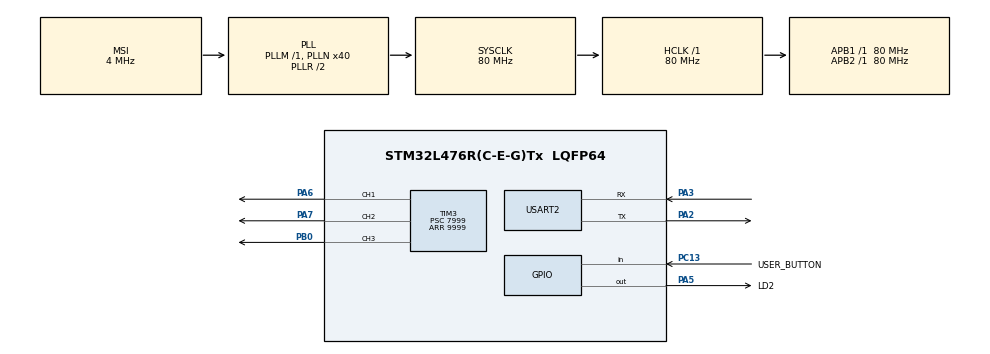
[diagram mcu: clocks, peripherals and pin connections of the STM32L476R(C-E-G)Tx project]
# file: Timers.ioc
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Mcu.Family=STM32L4
Mcu.Name=STM32L476R(C-E-G)Tx
Mcu.Package=LQFP64
NVIC.PriorityGroup=NVIC_PRIORITYGROUP_4
NVIC.TIM3_IRQn=true\:10\:0\:true\:false\:true\:true\:true\:true
PA13\ (JTMS-SWDIO).Mode=Serial_Wire
PA13\ (JTMS-SWDIO).Signal=SYS_JTMS-SWDIO
PA14\ (JTCK-SWCLK).Mode=Serial_Wire
PA14\ (JTCK-SWCLK).Signal=SYS_JTCK-SWCLK
PA2.Mode=Asynchronous
PA2.Signal=USART2_TX
PA3.Mode=Asynchronous
PA3.Signal=USART2_RX
PA5.GPIO_Label=LD2
PA5.Signal=GPIO_Output
PA6.Signal=S_TIM3_CH1
PA7.Signal=S_TIM3_CH2
PB0.Signal=S_TIM3_CH3
PC13.GPIO_Label=USER_BUTTON
PC13.Signal=GPIO_Input
ProjectManager.HeapSize=0x200
ProjectManager.StackSize=0x400
ProjectManager.TargetToolchain=STM32CubeIDE
RCC.AHBFreq_Value=80000000
RCC.APB1Freq_Value=80000000
RCC.APB1TimFreq_Value=80000000
RCC.APB2Freq_Value=80000000
RCC.APB2TimFreq_Value=80000000
RCC.CortexFreq_Value=80000000
RCC.HCLKFreq_Value=80000000
RCC.HSE_VALUE=8000000
RCC.HSI_VALUE=16000000
RCC.LSE_VALUE=32768
RCC.MSI_VALUE=4000000
RCC.PLLN=40
RCC.SYSCLKFreq_VALUE=80000000
RCC.SYSCLKSource=RCC_SYSCLKSOURCE_PLLCLK
RCC.VCOOutputFreq_Value=160000000
SH.S_TIM3_CH1.0=TIM3_CH1,PWM Generation1 CH1
SH.S_TIM3_CH2.0=TIM3_CH2,PWM Generation2 CH2
SH.S_TIM3_CH3.0=TIM3_CH3,PWM Generation3 CH3
TIM3.Channel-PWM\ Generation1\ CH1=TIM_CHANNEL_1
TIM3.Channel-PWM\ Generation2\ CH2=TIM_CHANNEL_2
TIM3.Channel-PWM\ Generation3\ CH3=TIM_CHANNEL_3
TIM3.OCPolarity_1=TIM_OCPOLARITY_LOW
TIM3.OCPolarity_2=TIM_OCPOLARITY_LOW
TIM3.OCPolarity_3=TIM_OCPOLARITY_LOW
TIM3.Period=9999
TIM3.Prescaler=7999
TIM3.Pulse-PWM\ Generation1\ CH1=2500
TIM3.Pulse-PWM\ Generation2\ CH2=5000
TIM3.Pulse-PWM\ Generation3\ CH3=7500
USART2.VirtualMode-Asynchronous=VM_ASYNC
VP_TIM3_VS_ClockSourceINT.Mode=Internal
board=custom

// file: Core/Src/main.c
/* USER CODE BEGIN Header */
/**
  ******************************************************************************
  * @file           : main.c
  * @brief          : Main program body
  ******************************************************************************
  * @attention
  *
  * Copyright (c) 2022 STMicroelectronics.
  * All rights reserved.
  *
  * This software is licensed under terms that can be found in the LICENSE file
  * in the root directory of this software component.
  * If no LICENSE file comes with this software, it is provided AS-IS.
  *
  ******************************************************************************
  */
/* USER CODE END Header */
#include "main.h"
#include "tim.h"
#include "usart.h"
#include "gpio.h"

void SystemClock_Config(void);

/* USER CODE BEGIN 0 */

void HAL_TIM_PeriodElapsedCallback(TIM_HandleTypeDef *htim)
{
	if (htim == &htim3)
		{
			HAL_GPIO_TogglePin(LD2_GPIO_Port, LD2_Pin);
		}
}

//void HAL_TIM_OC_DelayElapsedCallback(TIM_HandleTypeDef *htim)
//{
//	if (htim == &htim3)
//	{
//		switch(HAL_TIM_GetActiveChannel(&htim3))
//		{
//		case HAL_TIM_ACTIVE_CHANNEL_1:
//			HAL_GPIO_WritePin(LED1_GPIO_Port, LED1_Pin, GPIO_PIN_RESET);
//		break;
//
//		case HAL_TIM_ACTIVE_CHANNEL_2:
//			HAL_GPIO_WritePin(LED2_GPIO_Port, LED2_Pin, GPIO_PIN_RESET);
//		break;
//
//		case HAL_TIM_ACTIVE_CHANNEL_3:
//			HAL_GPIO_WritePin(LED3_GPIO_Port, LED3_Pin, GPIO_PIN_RESET);
//		break;
//
//		default:
//		break;
//		}
//	}
//}

/* USER CODE END 0 */

int main(void)
{

  /* MCU Configuration--------------------------------------------------------*/

  /* Reset of all peripherals, Initializes the Flash interface and the Systick. */
  HAL_Init();

  /* Configure the system clock */
  SystemClock_Config();

  /* Initialize all configured peripherals */
  MX_GPIO_Init();
  MX_USART2_UART_Init();
  MX_TIM3_Init();
  /* USER CODE BEGIN 2 */

  HAL_TIM_Base_Start_IT(&htim3);
  HAL_TIM_PWM_Start(&htim3, TIM_CHANNEL_1);
  HAL_TIM_PWM_Start(&htim3, TIM_CHANNEL_2);
  HAL_TIM_PWM_Start(&htim3, TIM_CHANNEL_3);

  /* USER CODE END 2 */

  /* Infinite loop */
  while (1)
  {

  }
}

void SystemClock_Config(void)
{
  RCC_OscInitTypeDef RCC_OscInitStruct = {0};
  RCC_ClkInitTypeDef RCC_ClkInitStruct = {0};

  /** Configure the main internal regulator output voltage
  */
  if (HAL_PWREx_ControlVoltageScaling(PWR_REGULATOR_VOLTAGE_SCALE1) != HAL_OK)
  {
    Error_Handler();
  }

  /** Initializes the RCC Oscillators according to the specified parameters
  * in the RCC_OscInitTypeDef structure.
  */
  RCC_OscInitStruct.OscillatorType = RCC_OSCILLATORTYPE_MSI;
  RCC_OscInitStruct.MSIState = RCC_MSI_ON;
  RCC_OscInitStruct.MSICalibrationValue = 0;
  RCC_OscInitStruct.MSIClockRange = RCC_MSIRANGE_6;
  RCC_OscInitStruct.PLL.PLLState = RCC_PLL_ON;
  RCC_OscInitStruct.PLL.PLLSource = RCC_PLLSOURCE_MSI;
  RCC_OscInitStruct.PLL.PLLM = 1;
  RCC_OscInitStruct.PLL.PLLN = 40;
  RCC_OscInitStruct.PLL.PLLP = RCC_PLLP_DIV7;
  RCC_OscInitStruct.PLL.PLLQ = RCC_PLLQ_DIV2;
  RCC_OscInitStruct.PLL.PLLR = RCC_PLLR_DIV2;
  if (HAL_RCC_OscConfig(&RCC_OscInitStruct) != HAL_OK)
  {
    Error_Handler();
  }

  /** Initializes the CPU, AHB and APB buses clocks
  */
  RCC_ClkInitStruct.ClockType = RCC_CLOCKTYPE_HCLK|RCC_CLOCKTYPE_SYSCLK
                              |RCC_CLOCKTYPE_PCLK1|RCC_CLOCKTYPE_PCLK2;
  RCC_ClkInitStruct.SYSCLKSource = RCC_SYSCLKSOURCE_PLLCLK;
  RCC_ClkInitStruct.AHBCLKDivider = RCC_SYSCLK_DIV1;
  RCC_ClkInitStruct.APB1CLKDivider = RCC_HCLK_DIV1;
  RCC_ClkInitStruct.APB2CLKDivider = RCC_HCLK_DIV1;

  if (HAL_RCC_ClockConfig(&RCC_ClkInitStruct, FLASH_LATENCY_4) != HAL_OK)
  {
    Error_Handler();
  }
}

void Error_Handler(void)
{
  __disable_irq();
  while (1)
  {
  }
}
